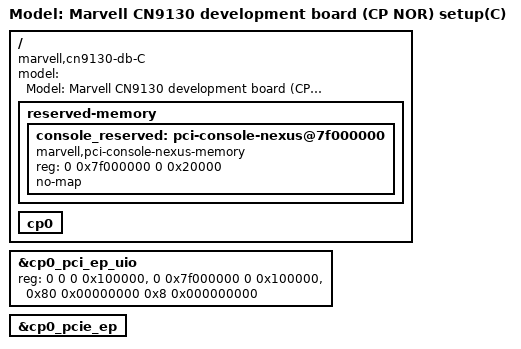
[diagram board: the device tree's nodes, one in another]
// SPDX-License-Identifier: (GPL-2.0+ OR MIT)

#include "cn9130-db-A.dts"

/ {
	model = "Model: Marvell CN9130 development board (CP NOR) setup(C)";
	compatible = "marvell,cn9130-db-C", "marvell,cn9130-db-A",
		     "marvell,armada-ap807-quad", "marvell,armada-ap807";

	reserved-memory {
		#address-cells = <2>;
		#size-cells = <2>;
		ranges;

		/* The PCI console memory must be reserved */
		console_reserved: pci-console-nexus@7f000000 {
			compatible = "marvell,pci-console-nexus-memory";
			reg = <0 0x7f000000 0 0x20000>;
			no-map;
		};
	};

	cp0 {
		/delete-node/ pcie@600000;
		/delete-node/ pcie@620000;
		/delete-node/ pcie@640000;
	};
};

&cp0_pci_ep_uio {
	reg = <0 0 0 0x100000>,
	      <0 0x7f000000 0 0x100000>,
	      <0x80 0x00000000 0x8 0x000000000>;
	reg-names = "bar0", "bar2", "host-map";
	status = "okay";
};

&cp0_pcie_ep {
	status = "okay";
};
